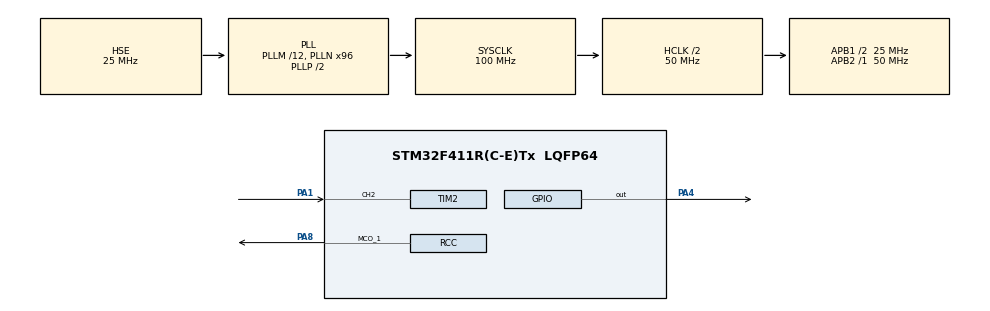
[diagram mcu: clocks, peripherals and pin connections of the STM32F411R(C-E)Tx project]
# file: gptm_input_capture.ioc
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Mcu.Family=STM32F4
Mcu.Name=STM32F411R(C-E)Tx
Mcu.Package=LQFP64
NVIC.PriorityGroup=NVIC_PRIORITYGROUP_4
NVIC.TIM2_IRQn=true\:0\:0\:false\:false\:true\:true\:true
NVIC.TIM3_IRQn=true\:0\:0\:false\:false\:true\:true\:true
PA1.Signal=S_TIM2_CH2
PA4.Signal=GPIO_Output
PA8.Mode=Clock-out-1
PA8.Signal=RCC_MCO_1
PH0\ -\ OSC_IN.Mode=HSE-External-Clock-Source
PH0\ -\ OSC_IN.Signal=RCC_OSC_IN
PH1\ -\ OSC_OUT.Mode=HSE-External-Clock-Source
PH1\ -\ OSC_OUT.Signal=RCC_OSC_OUT
ProjectManager.HeapSize=0x200
ProjectManager.StackSize=0x400
ProjectManager.TargetToolchain=STM32CubeIDE
RCC.48MHZClocksFreq_Value=50000000
RCC.AHBCLKDivider=RCC_SYSCLK_DIV2
RCC.AHBFreq_Value=50000000
RCC.APB1CLKDivider=RCC_HCLK_DIV2
RCC.APB1Freq_Value=25000000
RCC.APB1TimFreq_Value=50000000
RCC.APB2Freq_Value=50000000
RCC.APB2TimFreq_Value=50000000
RCC.CortexFreq_Value=50000000
RCC.HCLKFreq_Value=50000000
RCC.HSE_VALUE=25000000
RCC.HSI_VALUE=16000000
RCC.LSE_VALUE=32768
RCC.PLLM=12
RCC.PLLN=96
RCC.PLLSourceVirtual=RCC_PLLSOURCE_HSE
RCC.RCC_MCODiv1=RCC_MCODIV_5
RCC.SYSCLKFreq_VALUE=100000000
RCC.SYSCLKSource=RCC_SYSCLKSOURCE_PLLCLK
RCC.VCOOutputFreq_Value=200000000
SH.S_TIM2_CH2.0=TIM2_CH2,Input_Capture2_from_TI2
TIM2.Channel-Input_Capture2_from_TI2=TIM_CHANNEL_2
TIM2.Period=49
TIM2.Prescaler=999
TIM3.Period=99
TIM3.Prescaler=9
VP_TIM2_VS_ClockSourceINT.Mode=Internal
VP_TIM3_VS_ClockSourceINT.Mode=Internal
board=custom

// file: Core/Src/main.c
/* USER CODE BEGIN Header */
/**
 ******************************************************************************
 * @file           : main.c
 * @brief          : Main program body
 ******************************************************************************
 * @attention
 *
 * <h2><center>&copy; Copyright (c) 2021 STMicroelectronics.
 * All rights reserved.</center></h2>
 *
 * This software component is licensed by ST under BSD 3-Clause license,
 * the "License"; You may not use this file except in compliance with the
 * License. You may obtain a copy of the License at:
 *                        opensource.org/licenses/BSD-3-Clause
 *
 ******************************************************************************
 */
/* USER CODE END Header */

#include "main.h"

/* USER CODE BEGIN Includes */
#include <stdbool.h>
/* USER CODE END Includes */

TIM_HandleTypeDef htim2;
TIM_HandleTypeDef htim3;

void SystemClock_Config(void);
static void MX_GPIO_Init(void);
static void MX_TIM2_Init(void);
static void MX_TIM3_Init(void);

/* USER CODE BEGIN 0 */
uint32_t input_capture[2] = { 0 };
volatile uint8_t count = 1;
bool input_capture_done = false;
uint32_t capture_difference = 0;
double signal_timer_period = 0.0;
double signal_freq = 0.0;
double tim2_freq = 0.0;
double tim2_res = 0.0;
/* USER CODE END 0 */

int main(void) {

	/* MCU Configuration--------------------------------------------------------*/

	/* Reset of all peripherals, Initializes the Flash interface and the Systick. */
	HAL_Init();

	/* Configure the system clock */
	SystemClock_Config();

	/* Initialize all configured peripherals */
	MX_GPIO_Init();
	MX_TIM2_Init();
	MX_TIM3_Init();
	/* USER CODE BEGIN 2 */
	HAL_TIM_IC_Start_IT(&htim2, TIM_CHANNEL_2);
	HAL_TIM_Base_Start_IT(&htim3);
	/* USER CODE END 2 */

	/* Infinite loop */
	while (1) {

		/* USER CODE BEGIN 3 */
		if (input_capture_done) {
			if (input_capture[1] > input_capture[0]) //incase of count reload between 2 captures
				capture_difference = input_capture[1] - input_capture[0];
			else {
				capture_difference = 49 - input_capture[0] + input_capture[1];
			}
			tim2_freq = (HAL_RCC_GetPCLK1Freq() * 2) / htim2.Init.Prescaler;
			tim2_res = 1 / tim2_freq;
			signal_timer_period = capture_difference * tim2_res;
			signal_freq = 1 / signal_timer_period;
			input_capture_done = false;
		}
	}
	/* USER CODE END 3 */
}

void SystemClock_Config(void) {
	RCC_OscInitTypeDef RCC_OscInitStruct = { 0 };
	RCC_ClkInitTypeDef RCC_ClkInitStruct = { 0 };

	/** Configure the main internal regulator output voltage
	 */
	__HAL_RCC_PWR_CLK_ENABLE();
	__HAL_PWR_VOLTAGESCALING_CONFIG(PWR_REGULATOR_VOLTAGE_SCALE1);
	/** Initializes the CPU, AHB and APB busses clocks
	 */
	RCC_OscInitStruct.OscillatorType = RCC_OSCILLATORTYPE_HSI
			| RCC_OSCILLATORTYPE_HSE;
	RCC_OscInitStruct.HSEState = RCC_HSE_BYPASS;
	RCC_OscInitStruct.HSIState = RCC_HSI_ON;
	RCC_OscInitStruct.HSICalibrationValue = RCC_HSICALIBRATION_DEFAULT;
	RCC_OscInitStruct.PLL.PLLState = RCC_PLL_ON;
	RCC_OscInitStruct.PLL.PLLSource = RCC_PLLSOURCE_HSE;
	RCC_OscInitStruct.PLL.PLLM = 12;
	RCC_OscInitStruct.PLL.PLLN = 96;
	RCC_OscInitStruct.PLL.PLLP = RCC_PLLP_DIV2;
	RCC_OscInitStruct.PLL.PLLQ = 4;
	if (HAL_RCC_OscConfig(&RCC_OscInitStruct) != HAL_OK) {
		Error_Handler();
	}
	/** Initializes the CPU, AHB and APB busses clocks
	 */
	RCC_ClkInitStruct.ClockType = RCC_CLOCKTYPE_HCLK | RCC_CLOCKTYPE_SYSCLK
			| RCC_CLOCKTYPE_PCLK1 | RCC_CLOCKTYPE_PCLK2;
	RCC_ClkInitStruct.SYSCLKSource = RCC_SYSCLKSOURCE_PLLCLK;
	RCC_ClkInitStruct.AHBCLKDivider = RCC_SYSCLK_DIV2;
	RCC_ClkInitStruct.APB1CLKDivider = RCC_HCLK_DIV2;
	RCC_ClkInitStruct.APB2CLKDivider = RCC_HCLK_DIV1;

	if (HAL_RCC_ClockConfig(&RCC_ClkInitStruct, FLASH_LATENCY_1) != HAL_OK) {
		Error_Handler();
	}
	HAL_RCC_MCOConfig(RCC_MCO1, RCC_MCO1SOURCE_HSI, RCC_MCODIV_5);
}

static void MX_TIM2_Init(void) {

	TIM_ClockConfigTypeDef sClockSourceConfig = { 0 };
	TIM_MasterConfigTypeDef sMasterConfig = { 0 };
	TIM_IC_InitTypeDef sConfigIC = { 0 };

	htim2.Instance = TIM2;
	htim2.Init.Prescaler = 999;
	htim2.Init.CounterMode = TIM_COUNTERMODE_UP;
	htim2.Init.Period = 49;
	htim2.Init.ClockDivision = TIM_CLOCKDIVISION_DIV1;
	htim2.Init.AutoReloadPreload = TIM_AUTORELOAD_PRELOAD_DISABLE;
	if (HAL_TIM_Base_Init(&htim2) != HAL_OK) {
		Error_Handler();
	}
	sClockSourceConfig.ClockSource = TIM_CLOCKSOURCE_INTERNAL;
	if (HAL_TIM_ConfigClockSource(&htim2, &sClockSourceConfig) != HAL_OK) {
		Error_Handler();
	}
	if (HAL_TIM_IC_Init(&htim2) != HAL_OK) {
		Error_Handler();
	}
	sMasterConfig.MasterOutputTrigger = TIM_TRGO_RESET;
	sMasterConfig.MasterSlaveMode = TIM_MASTERSLAVEMODE_DISABLE;
	if (HAL_TIMEx_MasterConfigSynchronization(&htim2, &sMasterConfig)
			!= HAL_OK) {
		Error_Handler();
	}
	sConfigIC.ICPolarity = TIM_INPUTCHANNELPOLARITY_RISING;
	sConfigIC.ICSelection = TIM_ICSELECTION_DIRECTTI;
	sConfigIC.ICPrescaler = TIM_ICPSC_DIV1;
	sConfigIC.ICFilter = 0;
	if (HAL_TIM_IC_ConfigChannel(&htim2, &sConfigIC, TIM_CHANNEL_2) != HAL_OK) {
		Error_Handler();
	}

}

static void MX_TIM3_Init(void) {

	TIM_ClockConfigTypeDef sClockSourceConfig = { 0 };
	TIM_MasterConfigTypeDef sMasterConfig = { 0 };

	htim3.Instance = TIM3;
	htim3.Init.Prescaler = 9;
	htim3.Init.CounterMode = TIM_COUNTERMODE_UP;
	htim3.Init.Period = 99;
	htim3.Init.ClockDivision = TIM_CLOCKDIVISION_DIV1;
	htim3.Init.AutoReloadPreload = TIM_AUTORELOAD_PRELOAD_DISABLE;
	if (HAL_TIM_Base_Init(&htim3) != HAL_OK) {
		Error_Handler();
	}
	sClockSourceConfig.ClockSource = TIM_CLOCKSOURCE_INTERNAL;
	if (HAL_TIM_ConfigClockSource(&htim3, &sClockSourceConfig) != HAL_OK) {
		Error_Handler();
	}
	sMasterConfig.MasterOutputTrigger = TIM_TRGO_RESET;
	sMasterConfig.MasterSlaveMode = TIM_MASTERSLAVEMODE_DISABLE;
	if (HAL_TIMEx_MasterConfigSynchronization(&htim3, &sMasterConfig)
			!= HAL_OK) {
		Error_Handler();
	}

}

static void MX_GPIO_Init(void) {
	GPIO_InitTypeDef GPIO_InitStruct = { 0 };

	/* GPIO Ports Clock Enable */
	__HAL_RCC_GPIOH_CLK_ENABLE();
	__HAL_RCC_GPIOA_CLK_ENABLE();

	/*Configure GPIO pin Output Level */
	HAL_GPIO_WritePin(GPIOA, GPIO_PIN_4, GPIO_PIN_RESET);

	/*Configure GPIO pin : PA4 */
	GPIO_InitStruct.Pin = GPIO_PIN_4;
	GPIO_InitStruct.Mode = GPIO_MODE_OUTPUT_PP;
	GPIO_InitStruct.Pull = GPIO_NOPULL;
	GPIO_InitStruct.Speed = GPIO_SPEED_FREQ_LOW;
	HAL_GPIO_Init(GPIOA, &GPIO_InitStruct);

	/*Configure GPIO pin : PA8 */
	GPIO_InitStruct.Pin = GPIO_PIN_8;
	GPIO_InitStruct.Mode = GPIO_MODE_AF_PP;
	GPIO_InitStruct.Pull = GPIO_NOPULL;
	GPIO_InitStruct.Speed = GPIO_SPEED_FREQ_LOW;
	GPIO_InitStruct.Alternate = GPIO_AF0_MCO;
	HAL_GPIO_Init(GPIOA, &GPIO_InitStruct);

}

/* USER CODE BEGIN 4 */
void HAL_TIM_IC_CaptureCallback(TIM_HandleTypeDef *htim) {
	if (htim->Instance == TIM2) {
		if (!input_capture_done) {
			if (count == 1) {
				input_capture[0] = __HAL_TIM_GET_COMPARE(htim, TIM_CHANNEL_2);
				count++;
			} else if (count == 2) {
				input_capture[0] = __HAL_TIM_GET_COMPARE(htim, TIM_CHANNEL_2);
				count = 1;
				input_capture_done = true;
			}
		}
	}
}

void HAL_TIM_PeriodElapsedCallback(TIM_HandleTypeDef *htim) {
	if (htim->Instance == TIM3)
		HAL_GPIO_TogglePin(GPIOA, GPIO_PIN_4);
}
/* USER CODE END 4 */

void Error_Handler(void) {
}

/************************ (C) COPYRIGHT STMicroelectronics *****END OF FILE****/
